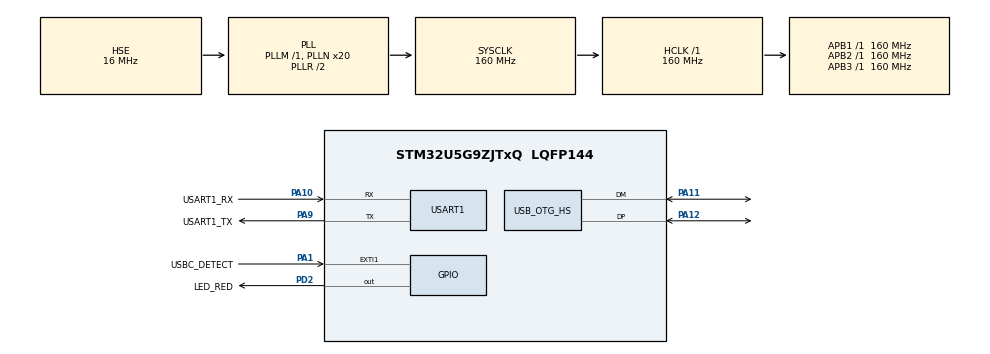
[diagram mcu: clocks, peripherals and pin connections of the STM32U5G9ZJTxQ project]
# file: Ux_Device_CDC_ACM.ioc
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CORTEX_M33_NS.userName=CORTEX_M33
GPDMA1.DIRECTION_GPDMACH0=DMA_MEMORY_TO_PERIPH
GPDMA1.IPHANDLE_GPDMACH0-SIMPLEREQUEST_GPDMACH0=__NULL
GPDMA1.REQUEST_GPDMACH0=GPDMA1_REQUEST_USART1_TX
GPDMA1.SRCINC_GPDMACH0=DMA_SINC_INCREMENTED
Mcu.Family=STM32U5
Mcu.Name=STM32U5G9ZJTxQ
Mcu.Package=LQFP144
NVIC.EXTI1_IRQn=true\:5\:0\:true\:false\:true\:false\:true\:true\:true
NVIC.GPDMA1_Channel0_IRQn=true\:0\:0\:false\:false\:true\:true\:true\:true\:true
NVIC.OTG_HS_IRQn=true\:7\:0\:true\:false\:true\:false\:true\:true\:true
NVIC.PriorityGroup=NVIC_PRIORITYGROUP_4
NVIC.TIM6_IRQn=true\:15\:0\:false\:false\:true\:false\:false\:true\:true
NVIC.TimeBase=TIM6_IRQn
NVIC.TimeBaseIP=TIM6
NVIC.USART1_IRQn=true\:6\:0\:true\:false\:true\:false\:true\:true\:true
PA1.GPIO_Label=USBC_DETECT
PA1.GPIO_ModeDefaultEXTI=GPIO_MODE_IT_RISING_FALLING
PA1.Signal=GPXTI1
PA10.GPIO_Label=USART1_RX
PA10.GPIO_PuPd=GPIO_PULLUP
PA10.GPIO_Speed=GPIO_SPEED_FREQ_HIGH
PA10.Mode=Asynchronous
PA10.Signal=USART1_RX
PA11.GPIO_Speed=GPIO_SPEED_FREQ_LOW
PA11.Mode=Internal_Phy_Device
PA11.Signal=USB_OTG_HS_DM
PA12.GPIO_Speed=GPIO_SPEED_FREQ_LOW
PA12.Mode=Internal_Phy_Device
PA12.Signal=USB_OTG_HS_DP
PA9.GPIO_Label=USART1_TX
PA9.GPIO_PuPd=GPIO_PULLUP
PA9.GPIO_Speed=GPIO_SPEED_FREQ_HIGH
PA9.Mode=Asynchronous
PA9.Signal=USART1_TX
PD2.GPIO_Label=LED_RED
PD2.GPIO_Speed=GPIO_SPEED_FREQ_HIGH
PD2.PinState=GPIO_PIN_SET
PD2.Signal=GPIO_Output
PH0-OSC_IN\ (PH0).Mode=HSE-External-Oscillator
PH0-OSC_IN\ (PH0).Signal=RCC_OSC_IN
PH1-OSC_OUT\ (PH1).Mode=HSE-External-Oscillator
PH1-OSC_OUT\ (PH1).Signal=RCC_OSC_OUT
PWR.PowerMode=PWR_SMPS_SUPPLY
ProjectManager.HeapSize=0x200
ProjectManager.StackSize=0x800
ProjectManager.TargetToolchain=EWARM V8.50
RCC.ADCFreq_Value=16000000
RCC.AHBFreq_Value=160000000
RCC.APB1Freq_Value=160000000
RCC.APB1TimFreq_Value=160000000
RCC.APB2Freq_Value=160000000
RCC.APB2TimFreq_Value=160000000
RCC.APB3Freq_Value=160000000
RCC.CortexFreq_Value=160000000
RCC.DACCLockSelectionVirtual=RCC_DAC1CLKSOURCE_LSI
RCC.EPOD_VALUE=16000000
RCC.HCLKFreq_Value=160000000
RCC.HSE_VALUE=16000000
RCC.HSI48_VALUE=48000000
RCC.HSI_VALUE=16000000
RCC.LSE_VALUE=32768
RCC.LSIDIV_VALUE=32000
RCC.MSIClockRange=RCC_MSIRANGE_0
RCC.MSI_VALUE=48000000
RCC.PLL1P=8
RCC.PLL2FRACN=0
RCC.PLL3FRACN=0
RCC.PLLFRACN=0
RCC.PLLN=20
RCC.PLLSourceVirtual=RCC_PLLSOURCE_HSE
RCC.SYSCLKFreq_VALUE=160000000
RCC.SYSCLKSource=RCC_SYSCLKSOURCE_PLLCLK
RCC.USBPHYCLockSelection=RCC_USBPHYCLKSOURCE_HSE
RCC.VCOOutputFreq_Value=320000000
USART1.VirtualMode-Asynchronous=VM_ASYNC
USBX.BSP.number=1
USBX.Core_System=1
USBX.MAX_POWER_IN_MILLI_AMPER=0
USBX.REG_USBX_DEVICE_CON_CK=0
USBX.USBD_CDCACM_EPINCMD_ADDR=2
USBX.USBD_CDCACM_EPIN_ADDR=1
USBX.USBD_CDCACM_EPIN_HS_MPS=512
USBX.USBD_CDCACM_EPOUT_HS_MPS=512
USBX.USBD_PID=22336
USBX.USBD_PRODUCT_STRING=STM32 Virtual ComPort
USBX.USBD_SERIAL_NUMBER=CDC_ACM001
USBX.USBX_SYS_SIZE=4*1024
USBX.UX_APP_MEM_POOL_SIZE=8192
USBX.UX_DEVICE_CDC_ACM=1
USBX.UX_DEVICE_CLASS_CDC_ACM_WRITE_AUTO_ZLP=1
USBX.UX_Device_Controller=1
USBX.UX_Device_CoreStack=1
USBX.UX_SLAVE_REQUEST_CONTROL_MAX_LENGTH=256
USBX.UX_SLAVE_REQUEST_DATA_MAX_LENGTH=512
USBX0.BSP.STBoard=false
USBX0.BSP.api=Unknown
USBX0.BSP.instance=USB_OTG_HS
USBX0.BSP.ip=USB_OTG_HS
USBX0.BSP.mode=Device_Only
USBX0.BSP.name=USBDevice
USBX0.BSP.solution=USB_OTG_HS
USB_OTG_HS.VirtualMode=Device_HS
VP_GPDMA1_VS_GPDMACH0.Mode=SIMPLEREQUEST_GPDMACH0
VP_ICACHE_VS_ICACHE.Mode=DirectMappedCache
VP_LPBAMQUEUE_VS_QUEUE.Mode=QUEUEMODE
VP_MEMORYMAP_VS_MEMORYMAP.Mode=CurAppReg
VP_PWR_VS_DBSignals.Mode=DisableDeadBatterySignals
VP_PWR_VS_LPOM.Mode=PowerOptimisation
VP_PWR_VS_SECSignals.Mode=Security/Privilege
VP_SYS_VS_tim6.Mode=TIM6
VP_THREADX_VS_RTOSJjThreadXJjCoreJjDefault.Mode=Core_Default
VP_USBX_Core_System.Mode=Core_System
VP_USBX_UX\ Device\ CDC\ ACM\ Class_HS.Mode=UX_Device_class_CDC_ACM_HS
VP_USBX_UX\ Device\ Controller_HS.Mode=UX_Device_Controller_HS
VP_USBX_UX\ Device\ CoreStack_HS.Mode=UX_Device_CoreStack_HS
board=custom

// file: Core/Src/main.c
/* USER CODE BEGIN Header */
/**
  ******************************************************************************
  * @file           : main.c
  * @brief          : Main program body
  ******************************************************************************
  * @attention
  *
  * Copyright (c) 2021 STMicroelectronics.
  * All rights reserved.
  *
  * This software is licensed under terms that can be found in the LICENSE file
  * in the root directory of this software component.
  * If no LICENSE file comes with this software, it is provided AS-IS.
  *
  ******************************************************************************
  */
/* USER CODE END Header */
#include "app_threadx.h"
#include "main.h"

UART_HandleTypeDef huart1;
DMA_HandleTypeDef handle_GPDMA1_Channel0;

PCD_HandleTypeDef hpcd_USB_OTG_HS;

void SystemClock_Config(void);
static void SystemPower_Config(void);
static void MX_GPIO_Init(void);
static void MX_GPDMA1_Init(void);
static void MX_ICACHE_Init(void);

int main(void)
{

  /* MCU Configuration--------------------------------------------------------*/

  /* Reset of all peripherals, Initializes the Flash interface and the Systick. */
  HAL_Init();

  /* Configure the System Power */
  SystemPower_Config();

  /* Configure the system clock */
  SystemClock_Config();

  /* Initialize all configured peripherals */
  MX_GPIO_Init();
  MX_GPDMA1_Init();
  MX_ICACHE_Init();
  MX_USART1_UART_Init();

  MX_ThreadX_Init();

  /* We should never get here as control is now taken by the scheduler */

  /* Infinite loop */
  while (1)
  {

  }
}

void SystemClock_Config(void)
{
  RCC_OscInitTypeDef RCC_OscInitStruct = {0};
  RCC_ClkInitTypeDef RCC_ClkInitStruct = {0};

  /** Configure the main internal regulator output voltage
  */
  if (HAL_PWREx_ControlVoltageScaling(PWR_REGULATOR_VOLTAGE_SCALE1) != HAL_OK)
  {
    Error_Handler();
  }

  /** Initializes the CPU, AHB and APB buses clocks
  */
  RCC_OscInitStruct.OscillatorType = RCC_OSCILLATORTYPE_HSE;
  RCC_OscInitStruct.HSEState = RCC_HSE_ON;
  RCC_OscInitStruct.PLL.PLLState = RCC_PLL_ON;
  RCC_OscInitStruct.PLL.PLLSource = RCC_PLLSOURCE_HSE;
  RCC_OscInitStruct.PLL.PLLMBOOST = RCC_PLLMBOOST_DIV1;
  RCC_OscInitStruct.PLL.PLLM = 1;
  RCC_OscInitStruct.PLL.PLLN = 20;
  RCC_OscInitStruct.PLL.PLLP = 8;
  RCC_OscInitStruct.PLL.PLLQ = 2;
  RCC_OscInitStruct.PLL.PLLR = 2;
  RCC_OscInitStruct.PLL.PLLRGE = RCC_PLLVCIRANGE_1;
  RCC_OscInitStruct.PLL.PLLFRACN = 0;
  if (HAL_RCC_OscConfig(&RCC_OscInitStruct) != HAL_OK)
  {
    Error_Handler();
  }

  /** Initializes the CPU, AHB and APB buses clocks
  */
  RCC_ClkInitStruct.ClockType = RCC_CLOCKTYPE_HCLK|RCC_CLOCKTYPE_SYSCLK
                              |RCC_CLOCKTYPE_PCLK1|RCC_CLOCKTYPE_PCLK2
                              |RCC_CLOCKTYPE_PCLK3;
  RCC_ClkInitStruct.SYSCLKSource = RCC_SYSCLKSOURCE_PLLCLK;
  RCC_ClkInitStruct.AHBCLKDivider = RCC_SYSCLK_DIV1;
  RCC_ClkInitStruct.APB1CLKDivider = RCC_HCLK_DIV1;
  RCC_ClkInitStruct.APB2CLKDivider = RCC_HCLK_DIV1;
  RCC_ClkInitStruct.APB3CLKDivider = RCC_HCLK_DIV1;

  if (HAL_RCC_ClockConfig(&RCC_ClkInitStruct, FLASH_LATENCY_4) != HAL_OK)
  {
    Error_Handler();
  }
}

/**
  * @brief Power Configuration
  * @retval None
  */
static void SystemPower_Config(void)
{

  /*
   * Disable the internal Pull-Up in Dead Battery pins of UCPD peripheral
   */
  HAL_PWREx_DisableUCPDDeadBattery();

  /*
   * Switch to SMPS regulator instead of LDO
   */
  if (HAL_PWREx_ConfigSupply(PWR_SMPS_SUPPLY) != HAL_OK)
  {
    Error_Handler();
  }
}

static void MX_GPDMA1_Init(void)
{

  /* Peripheral clock enable */
  __HAL_RCC_GPDMA1_CLK_ENABLE();

  /* GPDMA1 interrupt Init */
    HAL_NVIC_SetPriority(GPDMA1_Channel0_IRQn, 0, 0);
    HAL_NVIC_EnableIRQ(GPDMA1_Channel0_IRQn);

}

static void MX_ICACHE_Init(void)
{

  /** Enable instruction cache in 1-way (direct mapped cache)
  */
  if (HAL_ICACHE_ConfigAssociativityMode(ICACHE_1WAY) != HAL_OK)
  {
    Error_Handler();
  }
  if (HAL_ICACHE_Enable() != HAL_OK)
  {
    Error_Handler();
  }

}

void MX_USART1_UART_Init(void)
{

  huart1.Instance = USART1;
  huart1.Init.BaudRate = 115200;
  huart1.Init.WordLength = UART_WORDLENGTH_8B;
  huart1.Init.StopBits = UART_STOPBITS_1;
  huart1.Init.Parity = UART_PARITY_NONE;
  huart1.Init.Mode = UART_MODE_TX_RX;
  huart1.Init.HwFlowCtl = UART_HWCONTROL_NONE;
  huart1.Init.OverSampling = UART_OVERSAMPLING_16;
  huart1.Init.OneBitSampling = UART_ONE_BIT_SAMPLE_DISABLE;
  huart1.Init.ClockPrescaler = UART_PRESCALER_DIV1;
  huart1.AdvancedInit.AdvFeatureInit = UART_ADVFEATURE_NO_INIT;
  if (HAL_UART_Init(&huart1) != HAL_OK)
  {
    Error_Handler();
  }
  if (HAL_UARTEx_SetTxFifoThreshold(&huart1, UART_TXFIFO_THRESHOLD_1_8) != HAL_OK)
  {
    Error_Handler();
  }
  if (HAL_UARTEx_SetRxFifoThreshold(&huart1, UART_RXFIFO_THRESHOLD_1_8) != HAL_OK)
  {
    Error_Handler();
  }
  if (HAL_UARTEx_DisableFifoMode(&huart1) != HAL_OK)
  {
    Error_Handler();
  }

}

void MX_USB_OTG_HS_PCD_Init(void)
{

  hpcd_USB_OTG_HS.Instance = USB_OTG_HS;
  hpcd_USB_OTG_HS.Init.dev_endpoints = 9;
  hpcd_USB_OTG_HS.Init.speed = PCD_SPEED_HIGH;
  hpcd_USB_OTG_HS.Init.phy_itface = USB_OTG_HS_EMBEDDED_PHY;
  hpcd_USB_OTG_HS.Init.Sof_enable = DISABLE;
  hpcd_USB_OTG_HS.Init.low_power_enable = DISABLE;
  hpcd_USB_OTG_HS.Init.lpm_enable = DISABLE;
  hpcd_USB_OTG_HS.Init.use_dedicated_ep1 = DISABLE;
  hpcd_USB_OTG_HS.Init.vbus_sensing_enable = DISABLE;
  hpcd_USB_OTG_HS.Init.dma_enable = DISABLE;
  if (HAL_PCD_Init(&hpcd_USB_OTG_HS) != HAL_OK)
  {
    Error_Handler();
  }
  /* USER CODE BEGIN USB_OTG_HS_Init 2 */
  HAL_PCDEx_SetRxFiFo(&hpcd_USB_OTG_HS, 0x200);
  HAL_PCDEx_SetTxFiFo(&hpcd_USB_OTG_HS, 0, USBD_MAX_EP0_SIZE / 4);
  HAL_PCDEx_SetTxFiFo(&hpcd_USB_OTG_HS, 1, USBD_CDCACM_EPIN_HS_MPS / 4);
  HAL_PCDEx_SetTxFiFo(&hpcd_USB_OTG_HS, 2, USBD_CDCACM_EPINCMD_HS_MPS / 4);

  /* USER CODE END USB_OTG_HS_Init 2 */

}

static void MX_GPIO_Init(void)
{
  GPIO_InitTypeDef GPIO_InitStruct = {0};

  /* GPIO Ports Clock Enable */
  __HAL_RCC_GPIOH_CLK_ENABLE();
  __HAL_RCC_GPIOA_CLK_ENABLE();
  __HAL_RCC_GPIOD_CLK_ENABLE();

  /*Configure GPIO pin Output Level */
  HAL_GPIO_WritePin(LED_RED_GPIO_Port, LED_RED_Pin, GPIO_PIN_SET);

  /*Configure GPIO pin : USBC_DETECT_Pin */
  GPIO_InitStruct.Pin = USBC_DETECT_Pin;
  GPIO_InitStruct.Mode = GPIO_MODE_IT_RISING_FALLING;
  GPIO_InitStruct.Pull = GPIO_NOPULL;
  HAL_GPIO_Init(USBC_DETECT_GPIO_Port, &GPIO_InitStruct);

  /*Configure GPIO pin : LED_RED_Pin */
  GPIO_InitStruct.Pin = LED_RED_Pin;
  GPIO_InitStruct.Mode = GPIO_MODE_OUTPUT_PP;
  GPIO_InitStruct.Pull = GPIO_NOPULL;
  GPIO_InitStruct.Speed = GPIO_SPEED_FREQ_HIGH;
  HAL_GPIO_Init(LED_RED_GPIO_Port, &GPIO_InitStruct);

  /* EXTI interrupt init*/
  HAL_NVIC_SetPriority(EXTI1_IRQn, 5, 0);
  HAL_NVIC_EnableIRQ(EXTI1_IRQn);

}

void HAL_TIM_PeriodElapsedCallback(TIM_HandleTypeDef *htim)
{
  if (htim->Instance == TIM6)
  {
    HAL_IncTick();
  }
}

void Error_Handler(void)
{
  /* USER CODE BEGIN Error_Handler_Debug */
  /* User can add his own implementation to report the HAL error return state */
  while (1)
  {
    HAL_GPIO_TogglePin(LED_RED_GPIO_Port, LED_RED_Pin);
    HAL_Delay(200);
  }
  /* USER CODE END Error_Handler_Debug */
}
